# cslr_gpio register map
Vendor: Texas Instruments
Peripheral module from a debugger description file.
Registers are 32-bit, access per field, reset 0x0 unless marked. A register's access mark holds for its fields unless they carry their own. Offsets are as the file gives them; lines under a group give offsets from that group; [hi:lo] are bit positions; {n}, {i} and the like mark numbered series; 'fields as' and 'values as' point back to an identical list; <NAME> marks a mode.

## GPIO — General Purpose Input Output
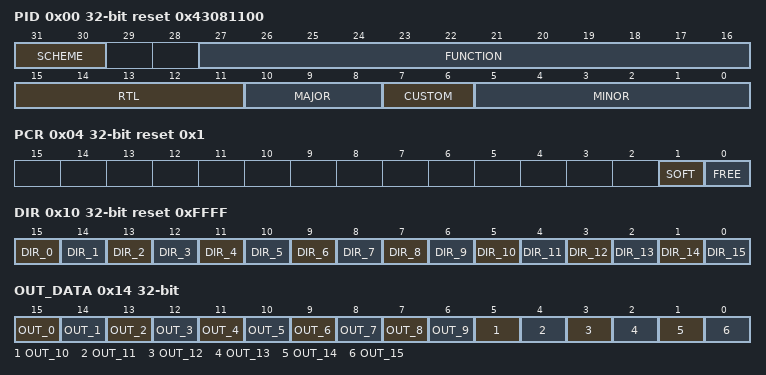
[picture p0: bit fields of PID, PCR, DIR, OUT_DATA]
0x00 PID ro reset 0x43081100 — Peripheral ID Register
  [31:30] SCHEME — Scheme of PID encoding
  [27:16] FUNCTION — Function for GPIO
  [15:11] RTL — RTL ID for this GPIO Module
  [10:8] MAJOR — Major ID for this GPIO module
  [7:6] CUSTOM — Custom ID for this GPIO Module
  [5:0] MINOR — Minor ID for this GPIO Module
0x04 PCR ro reset 0x1 — Peripheral Control Register
  [1] SOFT — Used along with FREE bit to determine the emulation suspend mode. Conventionally, when FREE bit is cleared, SOFT bit selects the mode. GPIO has FREE = 1, so SOFT bit does not affect functionality
  [0] FREE — For GPIO, the FREE bit is fixed at 1, which means GPIO runs free in emulation suspend mode
0x08 BINTEN — GPIO Interrupt Per-Bank Enable Register
  [0] EN rw — Per-bank interrupt enable
    0=DISABLE (Disables interrupt); 1=ENABLE (Enables interrupt)
0x10 DIR reset 0xFFFF — GPIO Direction Register
  [all] fields
    0=OUT (Output); 1=IN (Input)
  [15-n] DIR_{n} rw (n=0..15) — Direction of GPIO bank bit 0...15. It selects the direction for 16 GPIO signals
0x14 OUT_DATA — GPIO Output Data Register
  [15-n] OUT_{n} rw (n=0..15) — Output drive state of GPIO bank bit 0...15 Bits 0-15 form 16 GPIO signals of the bank Does not affect operation when it is configured as input. Reading it returns the output drive state
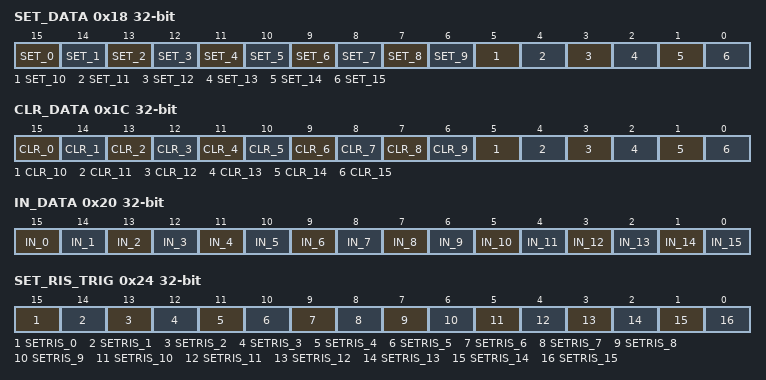
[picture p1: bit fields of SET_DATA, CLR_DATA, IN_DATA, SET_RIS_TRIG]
0x18 SET_DATA — GPIO Set Data Register
  [all] fields
    1=SET (Set output to 1)
  [15-n] SET_{n} rw (n=0..15) — Set output drive state of GPIO bank 0...15 Bits 0-15 form 16 GPIO signals of the bank Writing 1 sets the output drive state of corresponding GPIO signal. Reading it returns the output drive state
0x1C CLR_DATA — GPIO Clear Data Register
  [all] fields
    1=CLR (Clear output to 0)
  [15-n] CLR_{n} rw (n=0..15) — Clear output drive state of GPIO bank bit 0...15 Bits 0-15 form 16 GPIO signals of the bank Writing 1 clears the output drive state of corresponding GPIO. Reading it returns the output drive state
0x20 IN_DATA ro (reset mask 0xFFFF0000) — GPIO Input Data Register
  [15-n] IN_{n} (n=0..15) — Status of GPIO bank bit 0...15 Bits 0-15 form 16 GPIO signals of the bank
0x24 SET_RIS_TRIG — GPIO Set Rising Edge Interrupt Register
  [all] fields
    1=ENABLE
  [15-n] SETRIS_{n} rw (n=0..15) — Enable Rising edge interrupt detection for GPIO bank bit 0...15 Bits 0-15 form 16 GPIO signals of the bank Reading returns state of RIS_TRG
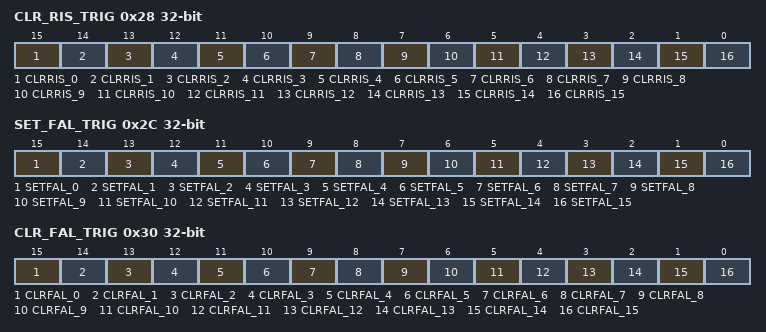
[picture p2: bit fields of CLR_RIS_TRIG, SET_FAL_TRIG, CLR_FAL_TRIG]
0x28 CLR_RIS_TRIG — GPIO Clear Rising Edge Interrupt Register
  [all] fields
    0=DISABLE
  [15-n] CLRRIS_{n} rw (n=0..15) — Disable Rising edge interrupt detection for GPIO bank bit 0...15 Bits 0-15 form 16 GPIO signals of the bank Reading returns complement state of RIS_TRG
0x2C SET_FAL_TRIG — GPIO Set Falling Edge Interrupt Register
  [all] fields
    1=ENABLE
  [15-n] SETFAL_{n} rw (n=0..15) — Enable Falling edge interrupt detection for GPIO bank bit 0...15 Bits 0-15 form 16 GPIO signals of the bank Reading returns state of FAL_TRG
0x30 CLR_FAL_TRIG — GPIO Clear Falling Edge Interrupt Register
  [all] fields
    0=DISABLE
  [15-n] CLRFAL_{n} rw (n=0..15) — Disable Falling edge interrupt detection for GPIO bank bit 0...15 Bits 0-15 form 16 GPIO signals of the bank Reading returns complement state of FAL_TRG
